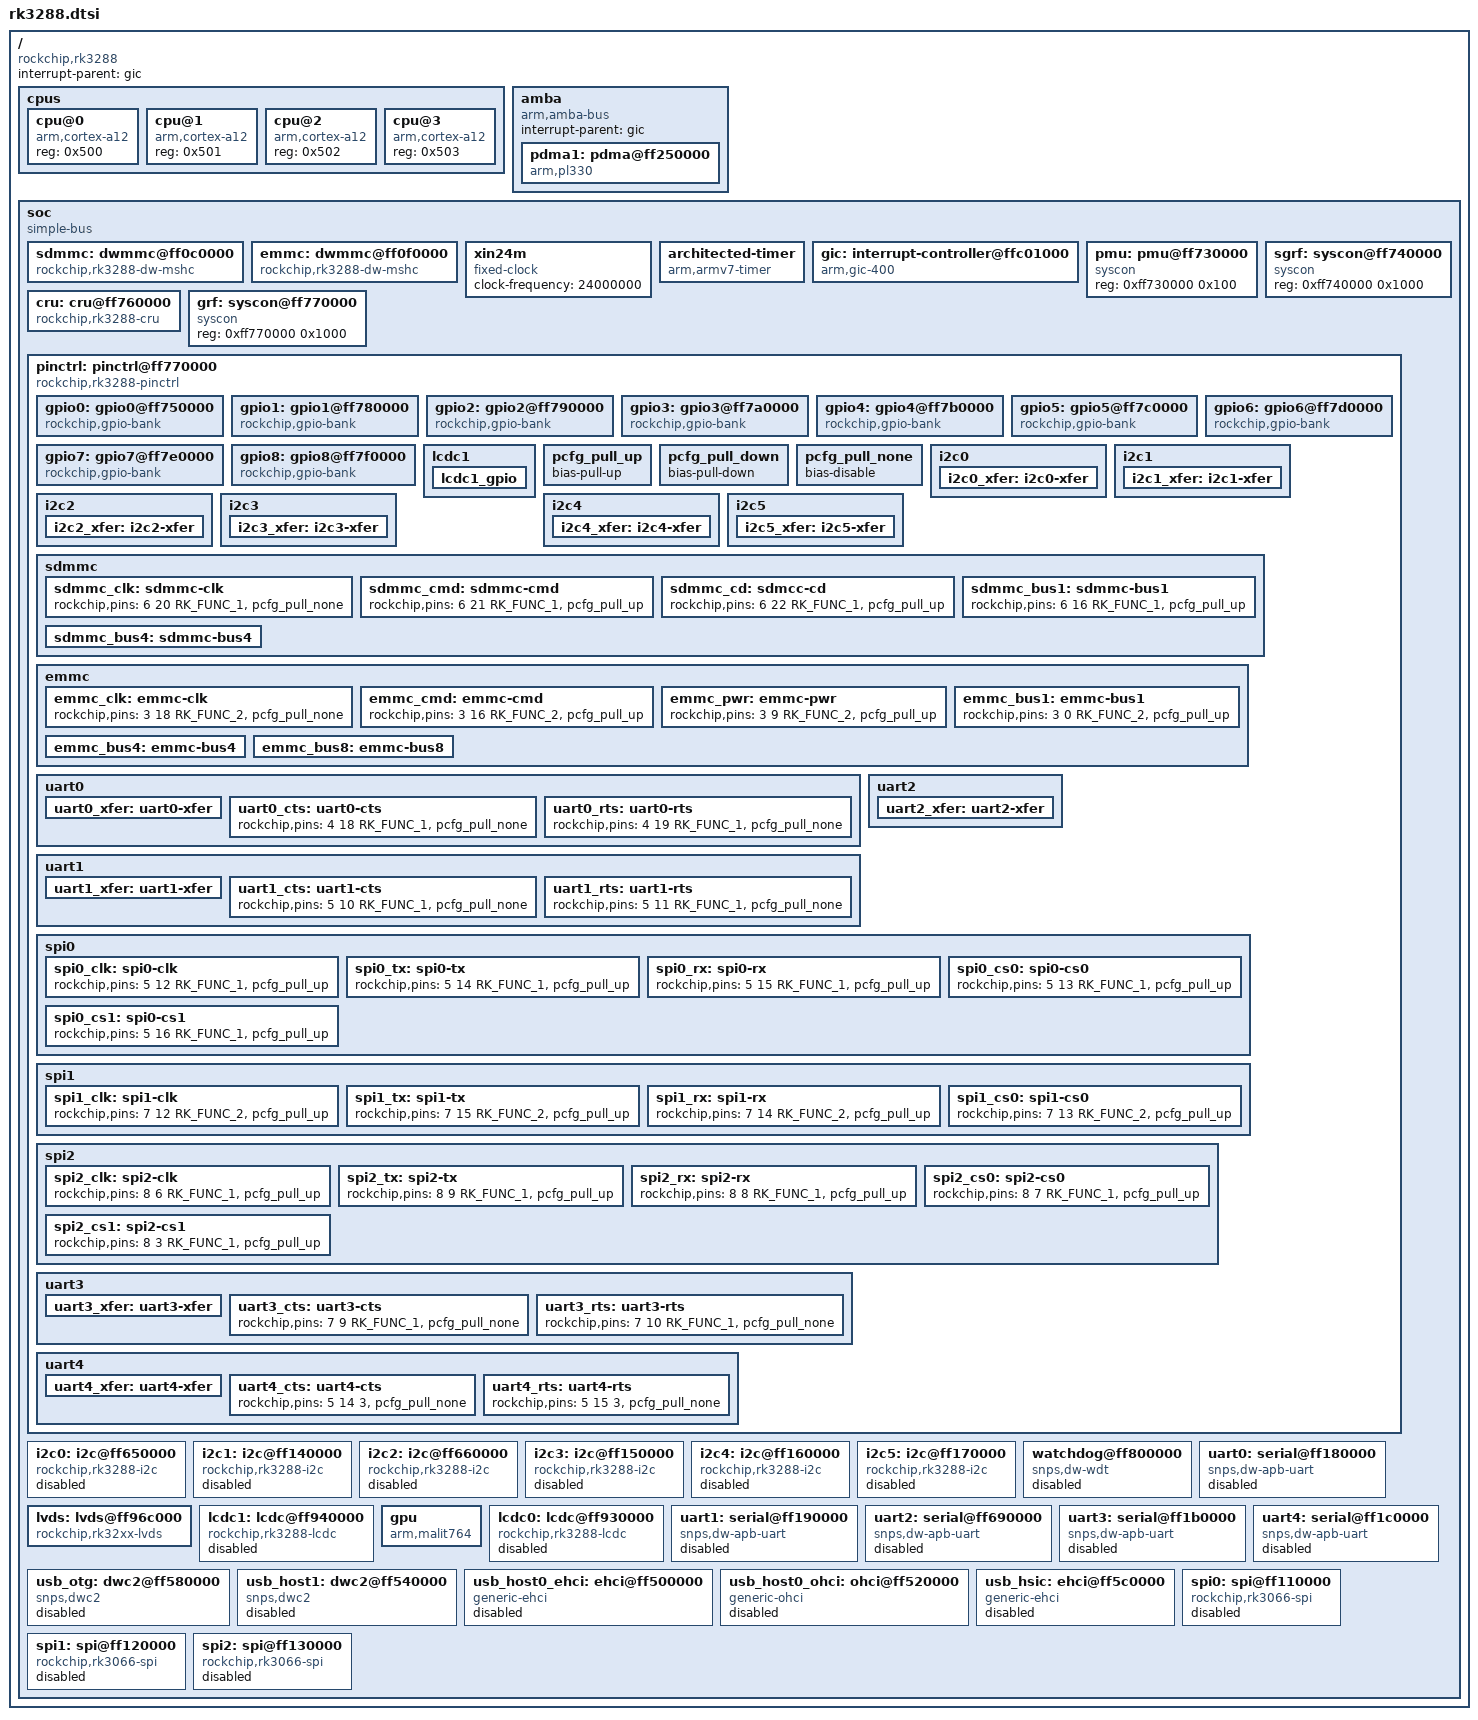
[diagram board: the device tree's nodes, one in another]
/*
 * This program is free software; you can redistribute it and/or modify
 * it under the terms of the GNU General Public License as published by
 * the Free Software Foundation; either version 2 of the License, or
 * (at your option) any later version.
 *
 * This program is distributed in the hope that it will be useful,
 * but WITHOUT ANY WARRANTY; without even the implied warranty of
 * MERCHANTABILITY or FITNESS FOR A PARTICULAR PURPOSE.  See the
 * GNU General Public License for more details.
 */

#include <dt-bindings/gpio/gpio.h>
#include <dt-bindings/interrupt-controller/irq.h>
#include <dt-bindings/interrupt-controller/arm-gic.h>
#include <dt-bindings/pinctrl/rockchip.h>
#include <dt-bindings/display/display.h>
#include <dt-bindings/clock/rk3288-cru.h>
#include "skeleton.dtsi"

/ {
	compatible = "rockchip,rk3288";

	interrupt-parent = <&gic>;

	cpus {
		#address-cells = <1>;
		#size-cells = <0>;

		cpu@0 {
			device_type = "cpu";
			compatible = "arm,cortex-a12";
			reg = <0x500>;
		};
		cpu@1 {
			device_type = "cpu";
			compatible = "arm,cortex-a12";
			reg = <0x501>;
		};
		cpu@2 {
			device_type = "cpu";
			compatible = "arm,cortex-a12";
			reg = <0x502>;
		};
		cpu@3 {
			device_type = "cpu";
			compatible = "arm,cortex-a12";
			reg = <0x503>;
		};
	};

	amba {
		#address-cells = <1>;
		#size-cells = <1>;
		compatible = "arm,amba-bus";
		interrupt-parent = <&gic>;
		ranges;

		pdma1: pdma@ff250000 {
			compatible = "arm,pl330", "arm,primecell";
			reg = <0xff250000 0x4000>;
			interrupts = <GIC_SPI 2 IRQ_TYPE_LEVEL_HIGH>,
                     <GIC_SPI 3 IRQ_TYPE_LEVEL_HIGH>;
			#dma-cells = <1>;
			#dma-channels = <8>;
			#dma-requests = <20>;
			clocks = <&cru ACLK_DMAC1>;
			clock-names = "apb_pclk";
		};
	};
	
	soc {
		#address-cells = <1>;
		#size-cells = <1>;
		compatible = "simple-bus";
		ranges;

		sdmmc: dwmmc@ff0c0000 {
			compatible = "rockchip,rk3288-dw-mshc";
			reg = <0xff0c0000 0x4000>;
			interrupts = <GIC_SPI 32 IRQ_TYPE_LEVEL_HIGH>;
			#address-cells = <1>;
			#size-cells = <0>;

			clocks = <&cru HCLK_SDMMC>, <&cru SCLK_SDMMC>;
			clock-names = "biu", "ciu";

			fifo-depth = <0x100>;
		};

		emmc: dwmmc@ff0f0000 {
			compatible = "rockchip,rk3288-dw-mshc";
			reg = <0xff0f0000 0x4000>;
			interrupts = <GIC_SPI 35 IRQ_TYPE_LEVEL_HIGH>;
			#address-cells = <1>;
			#size-cells = <0>;

			clocks = <&cru HCLK_EMMC>, <&cru SCLK_EMMC>;
			clock-names = "biu", "ciu";

			fifo-depth = <0x100>;
		};

		xin24m: xin24m {
			compatible = "fixed-clock";
			clock-frequency = <24000000>;
			#clock-cells = <0>;
		};

		architected-timer {
			compatible = "arm,armv7-timer";
			interrupts = <GIC_PPI 13 (GIC_CPU_MASK_SIMPLE(4) | IRQ_TYPE_LEVEL_HIGH)>,
				     <GIC_PPI 14 (GIC_CPU_MASK_SIMPLE(4) | IRQ_TYPE_LEVEL_HIGH)>,
				     <GIC_PPI 11 (GIC_CPU_MASK_SIMPLE(4) | IRQ_TYPE_LEVEL_HIGH)>,
				     <GIC_PPI 10 (GIC_CPU_MASK_SIMPLE(4) | IRQ_TYPE_LEVEL_HIGH)>;
			clock-frequency = <24000000>;
		};

		gic: interrupt-controller@ffc01000 {
			compatible = "arm,gic-400";
			interrupt-controller;
			#interrupt-cells = <3>;
			#address-cells = <0>;

			reg = <0xffc01000 0x1000>,
			      <0xffc02000 0x1000>,
			      <0xffc04000 0x2000>,
			      <0xffc06000 0x2000>;
			interrupts = <GIC_PPI 9 0xf04>;
		};

		pmu: pmu@ff730000 {
			compatible = "syscon";
			reg = <0xff730000 0x100>;
		};

		sgrf: syscon@ff740000 {
			compatible = "syscon";
			reg = <0xff740000 0x1000>;
		};

		cru: cru@ff760000 {
			compatible = "rockchip,rk3288-cru";
			reg = <0xff760000 0x1000>;
			rockchip,grf = <&grf>;

			#clock-cells = <1>;
			#reset-cells = <1>;
		};

		grf: syscon@ff770000 {
			compatible = "syscon";
			reg = <0xff770000 0x1000>;
		};

		pinctrl: pinctrl@ff770000 {
			compatible = "rockchip,rk3288-pinctrl";
			rockchip,grf = <&grf>;
			rockchip,pmu = <&pmu>;

			#address-cells = <1>;
			#size-cells = <1>;
			ranges;

			gpio0: gpio0@ff750000 {
				compatible = "rockchip,gpio-bank";
				reg =	<0xff750000 0x100>;
				interrupts = <GIC_SPI 81 IRQ_TYPE_LEVEL_HIGH>;
				clocks = <&cru PCLK_GPIO0>;

				gpio-controller;
				#gpio-cells = <2>;

				interrupt-controller;
				#interrupt-cells = <2>;
			};

			gpio1: gpio1@ff780000 {
				compatible = "rockchip,gpio-bank";
				reg = <0xff780000 0x100>;
				interrupts = <GIC_SPI 82 IRQ_TYPE_LEVEL_HIGH>;
				clocks = <&cru PCLK_GPIO1>;

				gpio-controller;
				#gpio-cells = <2>;

				interrupt-controller;
				#interrupt-cells = <2>;
			};

			gpio2: gpio2@ff790000 {
				compatible = "rockchip,gpio-bank";
				reg = <0xff790000 0x100>;
				interrupts = <GIC_SPI 83 IRQ_TYPE_LEVEL_HIGH>;
				clocks = <&cru PCLK_GPIO2>;

				gpio-controller;
				#gpio-cells = <2>;

				interrupt-controller;
				#interrupt-cells = <2>;
			};

			gpio3: gpio3@ff7a0000 {
				compatible = "rockchip,gpio-bank";
				reg = <0xff7a0000 0x100>;
				interrupts = <GIC_SPI 84 IRQ_TYPE_LEVEL_HIGH>;
				clocks = <&cru PCLK_GPIO3>;

				gpio-controller;
				#gpio-cells = <2>;

				interrupt-controller;
				#interrupt-cells = <2>;
			};

			gpio4: gpio4@ff7b0000 {
				compatible = "rockchip,gpio-bank";
				reg = <0xff7b0000 0x100>;
				interrupts = <GIC_SPI 85 IRQ_TYPE_LEVEL_HIGH>;
				clocks = <&cru PCLK_GPIO4>;

				gpio-controller;
				#gpio-cells = <2>;

				interrupt-controller;
				#interrupt-cells = <2>;
			};

			gpio5: gpio5@ff7c0000 {
				compatible = "rockchip,gpio-bank";
				reg = <0xff7c0000 0x100>;
				interrupts = <GIC_SPI 86 IRQ_TYPE_LEVEL_HIGH>;
				clocks = <&cru PCLK_GPIO5>;

				gpio-controller;
				#gpio-cells = <2>;

				interrupt-controller;
				#interrupt-cells = <2>;
			};

			gpio6: gpio6@ff7d0000 {
				compatible = "rockchip,gpio-bank";
				reg = <0xff7d0000 0x100>;
				interrupts = <GIC_SPI 87 IRQ_TYPE_LEVEL_HIGH>;
				clocks = <&cru PCLK_GPIO6>;

				gpio-controller;
				#gpio-cells = <2>;

				interrupt-controller;
				#interrupt-cells = <2>;
			};

			gpio7: gpio7@ff7e0000 {
				compatible = "rockchip,gpio-bank";
				reg = <0xff7e0000 0x100>;
				interrupts = <GIC_SPI 88 IRQ_TYPE_LEVEL_HIGH>;
				clocks = <&cru PCLK_GPIO7>;

				gpio-controller;
				#gpio-cells = <2>;

				interrupt-controller;
				#interrupt-cells = <2>;
			};

			gpio8: gpio8@ff7f0000 {
				compatible = "rockchip,gpio-bank";
				reg = <0xff7f0000 0x100>;
				interrupts = <GIC_SPI 89 IRQ_TYPE_LEVEL_HIGH>;
				clocks = <&cru PCLK_GPIO8>;

				gpio-controller;
				#gpio-cells = <2>;

				interrupt-controller;
				#interrupt-cells = <2>;
			};
			lcdc1 {
				lcdc1_gpio:lcdc1_gpio {
					rockchip,pins = <RK_GPIO1 32 RK_FUNC_GPIO &pcfg_pull_none>,
							<RK_GPIO1 33 RK_FUNC_GPIO &pcfg_pull_none>,
							<RK_GPIO1 34 RK_FUNC_GPIO &pcfg_pull_none>,
							<RK_GPIO1 35 RK_FUNC_GPIO &pcfg_pull_none>;
	   			};
	   		};

			pcfg_pull_up: pcfg_pull_up {
				bias-pull-up;
			};

			pcfg_pull_down: pcfg_pull_down {
				bias-pull-down;
			};

			pcfg_pull_none: pcfg_pull_none {
				bias-disable;
			};

			i2c0 {
				i2c0_xfer: i2c0-xfer {
					rockchip,pins = <0 15 RK_FUNC_1 &pcfg_pull_none>,
							<0 16 RK_FUNC_1 &pcfg_pull_none>;
				};
			};

			i2c1 {
				i2c1_xfer: i2c1-xfer {
					rockchip,pins = <8 4 RK_FUNC_1 &pcfg_pull_none>,
							<8 5 RK_FUNC_1 &pcfg_pull_none>;
				};
			};

			i2c2 {
				i2c2_xfer: i2c2-xfer {
					rockchip,pins = <6 9 RK_FUNC_1 &pcfg_pull_none>,
							<6 10 RK_FUNC_1 &pcfg_pull_none>;
				};
			};

			i2c3 {
				i2c3_xfer: i2c3-xfer {
					rockchip,pins = <2 16 RK_FUNC_1 &pcfg_pull_none>,
							<2 17 RK_FUNC_1 &pcfg_pull_none>;
				};
			};

			i2c4 {
				i2c4_xfer: i2c4-xfer {
					rockchip,pins = <7 17 RK_FUNC_1 &pcfg_pull_none>,
							<7 18 RK_FUNC_1 &pcfg_pull_none>;
				};
			};

			i2c5 {
				i2c5_xfer: i2c5-xfer {
					rockchip,pins = <7 19 RK_FUNC_1 &pcfg_pull_none>,
							<7 20 RK_FUNC_1 &pcfg_pull_none>;
				};
			};

			sdmmc {
				sdmmc_clk: sdmmc-clk {
					rockchip,pins = <6 20 RK_FUNC_1 &pcfg_pull_none>;
				};

				sdmmc_cmd: sdmmc-cmd {
					rockchip,pins = <6 21 RK_FUNC_1 &pcfg_pull_up>;
				};

				sdmmc_cd: sdmcc-cd {
					rockchip,pins = <6 22 RK_FUNC_1 &pcfg_pull_up>;
				};

				sdmmc_bus1: sdmmc-bus1 {
					rockchip,pins = <6 16 RK_FUNC_1 &pcfg_pull_up>;
				};

				sdmmc_bus4: sdmmc-bus4 {
					rockchip,pins = <6 16 RK_FUNC_1 &pcfg_pull_up>,
							<6 17 RK_FUNC_1 &pcfg_pull_up>,
							<6 18 RK_FUNC_1 &pcfg_pull_up>,
							<6 19 RK_FUNC_1 &pcfg_pull_up>;
				};
			};

			emmc {
				emmc_clk: emmc-clk {
					rockchip,pins = <3 18 RK_FUNC_2 &pcfg_pull_none>;
				};

				emmc_cmd: emmc-cmd {
					rockchip,pins = <3 16 RK_FUNC_2 &pcfg_pull_up>;
				};

				emmc_pwr: emmc-pwr {
					rockchip,pins = <3 9 RK_FUNC_2 &pcfg_pull_up>;
				};

				emmc_bus1: emmc-bus1 {
					rockchip,pins = <3 0 RK_FUNC_2 &pcfg_pull_up>;
				};

				emmc_bus4: emmc-bus4 {
					rockchip,pins = <3 0 RK_FUNC_2 &pcfg_pull_up>,
							<3 1 RK_FUNC_2 &pcfg_pull_up>,
							<3 2 RK_FUNC_2 &pcfg_pull_up>,
							<3 3 RK_FUNC_2 &pcfg_pull_up>;
				};

				emmc_bus8: emmc-bus8 {
					rockchip,pins = <3 0 RK_FUNC_2 &pcfg_pull_up>,
							<3 1 RK_FUNC_2 &pcfg_pull_up>,
							<3 2 RK_FUNC_2 &pcfg_pull_up>,
							<3 3 RK_FUNC_2 &pcfg_pull_up>,
							<3 4 RK_FUNC_2 &pcfg_pull_up>,
							<3 5 RK_FUNC_2 &pcfg_pull_up>,
							<3 6 RK_FUNC_2 &pcfg_pull_up>,
							<3 7 RK_FUNC_2 &pcfg_pull_up>;
				};
			};

			uart0 {
				uart0_xfer: uart0-xfer {
					rockchip,pins = <4 16 RK_FUNC_1 &pcfg_pull_up>,
							<4 17 RK_FUNC_1 &pcfg_pull_none>;
				};

				uart0_cts: uart0-cts {
					rockchip,pins = <4 18 RK_FUNC_1 &pcfg_pull_none>;
				};

				uart0_rts: uart0-rts {
					rockchip,pins = <4 19 RK_FUNC_1 &pcfg_pull_none>;
				};
			};

			uart1 {
				uart1_xfer: uart1-xfer {
					rockchip,pins = <5 8 RK_FUNC_1 &pcfg_pull_up>,
							<5 9 RK_FUNC_1 &pcfg_pull_none>;
				};

				uart1_cts: uart1-cts {
					rockchip,pins = <5 10 RK_FUNC_1 &pcfg_pull_none>;
				};

				uart1_rts: uart1-rts {
					rockchip,pins = <5 11 RK_FUNC_1 &pcfg_pull_none>;
				};
			};

			uart2 {
				uart2_xfer: uart2-xfer {
					rockchip,pins = <7 22 RK_FUNC_1 &pcfg_pull_up>,
							<7 23 RK_FUNC_1 &pcfg_pull_none>;
				};
				/* no rts / cts for uart2 */
			};
			
			spi0 {
				spi0_clk: spi0-clk {
					rockchip,pins = <5 12 RK_FUNC_1 &pcfg_pull_up>;
				};
				spi0_tx: spi0-tx {
					rockchip,pins = <5 14 RK_FUNC_1 &pcfg_pull_up>;
				};
				spi0_rx: spi0-rx {
					rockchip,pins = <5 15 RK_FUNC_1 &pcfg_pull_up>;
				};
				spi0_cs0: spi0-cs0 {
					rockchip,pins = <5 13 RK_FUNC_1 &pcfg_pull_up>;
				};
				spi0_cs1: spi0-cs1 {
					rockchip,pins = <5 16 RK_FUNC_1 &pcfg_pull_up>;
				};
			};
			spi1 {
				spi1_clk: spi1-clk {
					rockchip,pins = <7 12 RK_FUNC_2 &pcfg_pull_up>;
				};
				spi1_tx: spi1-tx {
					rockchip,pins = <7 15 RK_FUNC_2 &pcfg_pull_up>;
				};
				spi1_rx: spi1-rx {
					rockchip,pins = <7 14 RK_FUNC_2 &pcfg_pull_up>;
				};
				spi1_cs0: spi1-cs0 {
					rockchip,pins = <7 13 RK_FUNC_2 &pcfg_pull_up>;
				};
			};

			spi2 {
				spi2_clk: spi2-clk {
					rockchip,pins = <8 6 RK_FUNC_1 &pcfg_pull_up>;
				};
				spi2_tx: spi2-tx {
					rockchip,pins = <8 9 RK_FUNC_1 &pcfg_pull_up>;
				};
				spi2_rx: spi2-rx {
					rockchip,pins = <8 8 RK_FUNC_1 &pcfg_pull_up>;
				};
				spi2_cs0: spi2-cs0 {
					rockchip,pins = <8 7 RK_FUNC_1 &pcfg_pull_up>;
				};
				spi2_cs1: spi2-cs1 {
					rockchip,pins = <8 3 RK_FUNC_1 &pcfg_pull_up>;
				};
			};

			uart3 {
				uart3_xfer: uart3-xfer {
					rockchip,pins = <7 7 RK_FUNC_1 &pcfg_pull_up>,
							<7 8 RK_FUNC_1 &pcfg_pull_none>;
				};

				uart3_cts: uart3-cts {
					rockchip,pins = <7 9 RK_FUNC_1 &pcfg_pull_none>;
				};

				uart3_rts: uart3-rts {
					rockchip,pins = <7 10 RK_FUNC_1 &pcfg_pull_none>;
				};
			};

			uart4 {
				uart4_xfer: uart4-xfer {
					rockchip,pins = <5 12 3 &pcfg_pull_up>,
							<5 13 3 &pcfg_pull_none>;
				};

				uart4_cts: uart4-cts {
					rockchip,pins = <5 14 3 &pcfg_pull_none>;
				};

				uart4_rts: uart4-rts {
					rockchip,pins = <5 15 3 &pcfg_pull_none>;
				};
			};
		};

		i2c0: i2c@ff650000 {
			compatible = "rockchip,rk3288-i2c";
			reg = <0xff650000 0x1000>;
			interrupts = <GIC_SPI 60 IRQ_TYPE_LEVEL_HIGH>;
			#address-cells = <1>;
			#size-cells = <0>;

			clock-names = "i2c";
			clocks = <&cru PCLK_I2C0>;

			status = "disabled";
		};

		i2c1: i2c@ff140000 {
			compatible = "rockchip,rk3288-i2c";
			reg = <0xff140000 0x1000>;
			interrupts = <GIC_SPI 62 IRQ_TYPE_LEVEL_HIGH>;
			#address-cells = <1>;
			#size-cells = <0>;

			clock-names = "i2c";
			clocks = <&cru PCLK_I2C1>;

			status = "disabled";
		};

		i2c2: i2c@ff660000 {
			compatible = "rockchip,rk3288-i2c";
			reg = <0xff660000 0x1000>;
			interrupts = <GIC_SPI 61 IRQ_TYPE_LEVEL_HIGH>;
			#address-cells = <1>;
			#size-cells = <0>;

			clock-names = "i2c";
			clocks = <&cru PCLK_I2C2>;

			status = "disabled";
		};

		i2c3: i2c@ff150000 {
			compatible = "rockchip,rk3288-i2c";
			reg = <0xff150000 0x1000>;
			interrupts = <GIC_SPI 63 IRQ_TYPE_LEVEL_HIGH>;
			#address-cells = <1>;
			#size-cells = <0>;

			clock-names = "i2c";
			clocks = <&cru PCLK_I2C3>;

			status = "disabled";
		};

		i2c4: i2c@ff160000 {
			compatible = "rockchip,rk3288-i2c";
			reg = <0xff160000 0x1000>;
			interrupts = <GIC_SPI 64 IRQ_TYPE_LEVEL_HIGH>;
			#address-cells = <1>;
			#size-cells = <0>;

			clock-names = "i2c";
			clocks = <&cru PCLK_I2C4>;

			status = "disabled";
		};

		i2c5: i2c@ff170000 {
			compatible = "rockchip,rk3288-i2c";
			reg = <0xff170000 0x1000>;
			interrupts = <GIC_SPI 65 IRQ_TYPE_LEVEL_HIGH>;
			#address-cells = <1>;
			#size-cells = <0>;

			clock-names = "i2c";
			clocks = <&cru PCLK_I2C5>;

			status = "disabled";
		};

		watchdog@ff800000 {
			compatible = "snps,dw-wdt";
			reg = <0xff800000 0x100>;
			interrupts = <GIC_SPI 111 IRQ_TYPE_LEVEL_HIGH>;
			status = "disabled";
		};

		uart0: serial@ff180000 {
			compatible = "snps,dw-apb-uart";
			reg = <0xff180000 0x100>;
			interrupts = <GIC_SPI 55 IRQ_TYPE_LEVEL_HIGH>;
			reg-shift = <2>;
			reg-io-width = <4>;
			clocks = <&cru SCLK_UART0>, <&cru PCLK_UART0>;
			clock-names = "baudclk", "apb_pclk";
			status = "disabled";
		};

		lvds: lvds@ff96c000 {
			compatible = "rockchip,rk32xx-lvds";
			rockchip,grf = <&grf>;
			reg = <0xff96c000 0x4000>;
			clocks = <&cru PCLK_LVDS_PHY>;
			clock-names = "pclk_lvds";
		};

		lcdc1: lcdc@ff940000 {
			compatible = "rockchip,rk3288-lcdc";
			rockchip,prop = <0>;
			rochchip,pwr18 = <0>;
			reg = <0xff940000 0x10000>;
			interrupts = <GIC_SPI 16 IRQ_TYPE_LEVEL_HIGH>;
			pinctrl-names = "default", "gpio";
			pinctrl-0 = <&lcdc1_gpio>;
			//pinctrl-1 = <&lcdc0_gpio>;
			status = "disabled";
			clocks = <&cru ACLK_VOP1>, <&cru DCLK_VOP1>, <&cru HCLK_VOP1>;
			clock-names = "aclk_lcdc", "dclk_lcdc", "hclk_lcdc";
		};

		gpu{
			compatible = "arm,malit764",
				     "arm,malit76x",
				     "arm,malit7xx",
				     "arm,mali-midgard";
			reg = <0xffa30000 0x10000>;
			interrupts = <GIC_SPI 6 IRQ_TYPE_LEVEL_HIGH>,
				     <GIC_SPI 7 IRQ_TYPE_LEVEL_HIGH>,
				     <GIC_SPI 8 IRQ_TYPE_LEVEL_HIGH>;
				interrupt-names = "JOB", "MMU", "GPU";
			
			clocks = <&cru SCLK_GPU>, <&cru ACLK_GPU>;
			clock-names = "sclk_gpu", "aclk_gpu";
		};

		lcdc0: lcdc@ff930000 {
			compatible = "rockchip,rk3288-lcdc";
			rockchip,prop = <1>;
			rockchip,pwr18 = <0>;
			reg = <0xff930000 0x10000>;
			interrupts = <GIC_SPI 15 IRQ_TYPE_LEVEL_HIGH>;
			status = "disabled";
			clocks = <&cru ACLK_VOP0>, <&cru DCLK_VOP0>, <&cru HCLK_VOP0>;
			clock-names = "aclk_lcdc", "dclk_lcdc", "hclk_lcdc";
		};

		uart1: serial@ff190000 {
			compatible = "snps,dw-apb-uart";
			reg = <0xff190000 0x100>;
			interrupts = <GIC_SPI 56 IRQ_TYPE_LEVEL_HIGH>;
			reg-shift = <2>;
			reg-io-width = <4>;
			clocks = <&cru SCLK_UART1>, <&cru PCLK_UART1>;
			clock-names = "baudclk", "apb_pclk";
			status = "disabled";
		};

		uart2: serial@ff690000 {
			compatible = "snps,dw-apb-uart";
			reg = <0xff690000 0x100>;
			interrupts = <GIC_SPI 57 IRQ_TYPE_LEVEL_HIGH>;
			reg-shift = <2>;
			reg-io-width = <4>;
			clocks = <&cru SCLK_UART2>, <&cru PCLK_UART2>;
			clock-names = "baudclk", "apb_pclk";
			status = "disabled";
			pinctrl-names = "default";
			pinctrl-0 = <&uart2_xfer>;
		};

		uart3: serial@ff1b0000 {
			compatible = "snps,dw-apb-uart";
			reg = <0xff1b0000 0x100>;
			interrupts = <GIC_SPI 58 IRQ_TYPE_LEVEL_HIGH>;
			reg-shift = <2>;
			reg-io-width = <4>;
			clocks = <&cru SCLK_UART3>, <&cru PCLK_UART3>;
			clock-names = "baudclk", "apb_pclk";
			status = "disabled";
		};

		uart4: serial@ff1c0000 {
			compatible = "snps,dw-apb-uart";
			reg = <0xff1c0000 0x100>;
			interrupts = <GIC_SPI 59 IRQ_TYPE_LEVEL_HIGH>;
			reg-shift = <2>;
			reg-io-width = <4>;
			clocks = <&cru SCLK_UART4>, <&cru PCLK_UART4>;
			clock-names = "baudclk", "apb_pclk";
			status = "disabled";
		};

		usb_otg: dwc2@ff580000 {
			compatible = "snps,dwc2";
			reg = <0xff580000 0x40000>;
			interrupts = <GIC_SPI 23 IRQ_TYPE_LEVEL_HIGH>;
			clocks = <&cru HCLK_OTG0>;
			clock-names = "otg";
			status = "disabled";
		};

		usb_host1: dwc2@ff540000 {
			compatible = "snps,dwc2";
			reg = <0xff540000 0x40000>;
			interrupts = <GIC_SPI 25 IRQ_TYPE_LEVEL_HIGH>;
			clocks = <&cru HCLK_USBHOST1>;
			clock-names = "otg";
			status = "disabled";
		};

		usb_host0_ehci: ehci@ff500000 {
			compatible = "generic-ehci";
			reg = <0xff500000 0x100>;
			interrupts = <GIC_SPI 24 IRQ_TYPE_LEVEL_HIGH>;
			clocks = <&cru HCLK_USBHOST0>;
			clock-names = "usbhost";
			status = "disabled";
		};

		/* NOTE: OHCI doesn't actually work on hardware */
		usb_host0_ohci: ohci@ff520000 {
			compatible = "generic-ohci";
			reg = <0xff520000 0x100>;
			interrupts = <GIC_SPI 24 IRQ_TYPE_LEVEL_HIGH>;
			clocks = <&cru HCLK_USBHOST0>;
			clock-names = "usbhost";
			status = "disabled";
		};

		usb_hsic: ehci@ff5c0000 {
			compatible = "generic-ehci";
			reg = <0xff5c0000 0x100>;
			interrupts = <GIC_SPI 26 IRQ_TYPE_LEVEL_HIGH>;
			clocks = <&cru HCLK_HSIC>;
			clock-names = "usbhost";
			status = "disabled";
		};

		spi0: spi@ff110000 {
			compatible = "rockchip,rk3066-spi";
			reg = <0xff110000 0x1000>;
			dmas = <&pdma1 11>, <&pdma1 12>;
			dma-names = "tx", "rx";
			#address-cells = <1>;
			#size-cells = <0>;
			interrupts = <GIC_SPI 44 IRQ_TYPE_LEVEL_HIGH>;
			pinctrl-names = "default";
			pinctrl-0 = <&spi0_clk &spi0_tx &spi0_rx &spi0_cs0 &spi0_cs1>;
			clocks = <&cru SCLK_SPI0>, <&cru PCLK_SPI0>;
			clock-names = "spiclk", "apb_pclk";
			status = "disabled";
		};

		spi1: spi@ff120000 {
			compatible = "rockchip,rk3066-spi";
			reg = <0xff120000 0x1000>;
			dmas = <&pdma1 13>, <&pdma1 14>;
			dma-names = "tx", "rx";
			#address-cells = <1>;
			#size-cells = <0>;
			interrupts = <GIC_SPI 45 IRQ_TYPE_LEVEL_HIGH>;
			pinctrl-names = "default";
			pinctrl-0 = <&spi1_clk &spi1_tx &spi1_rx &spi1_cs0>;
			clocks = <&cru SCLK_SPI1>, <&cru PCLK_SPI1>;
			clock-names = "spiclk", "apb_pclk";
			status = "disabled";
		};

		spi2: spi@ff130000 {
			compatible = "rockchip,rk3066-spi";
			reg = <0xff130000 0x1000>;
			dmas = <&pdma1 15>, <&pdma1 16>;
			dma-names = "tx", "rx";
			#address-cells = <1>;
			#size-cells = <0>;
			interrupts = <GIC_SPI 46 IRQ_TYPE_LEVEL_HIGH>;
			pinctrl-names = "default";
			pinctrl-0 = <&spi2_clk &spi2_tx &spi2_rx &spi2_cs0 &spi2_cs1>;
			clocks = <&cru SCLK_SPI2>, <&cru PCLK_SPI2>;
			clock-names = "spiclk", "apb_pclk";
			status = "disabled";
		};
	};
};
